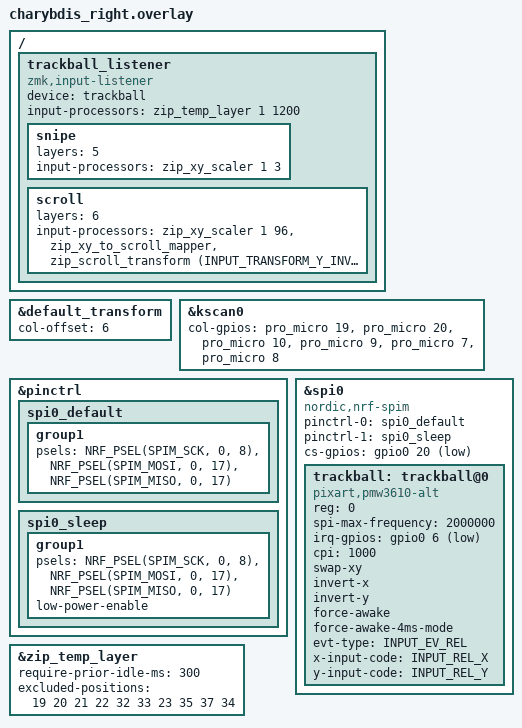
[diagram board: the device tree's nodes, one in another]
/*
 * Copyright (c) 2020 ZMK Contributors
 *
 * SPDX-License-Identifier: MIT
 */

#include <zephyr/dt-bindings/input/input-event-codes.h>
#include <dt-bindings/zmk/input_transform.h>
#include <input/processors.dtsi>

#include "charybdis.dtsi"

&default_transform {
	col-offset = <6>;
};

&kscan0 {
	col-gpios
		= <&pro_micro 19 GPIO_ACTIVE_HIGH>
		, <&pro_micro 20 GPIO_ACTIVE_HIGH>
		, <&pro_micro 10 GPIO_ACTIVE_HIGH>
		, <&pro_micro 9 GPIO_ACTIVE_HIGH>
		, <&pro_micro 7 GPIO_ACTIVE_HIGH>
		, <&pro_micro 8 GPIO_ACTIVE_HIGH>
		;
};

// trackball bus
&pinctrl {
    spi0_default: spi0_default {
        group1 {
            psels = <NRF_PSEL(SPIM_SCK, 0, 8)>,
                <NRF_PSEL(SPIM_MOSI, 0, 17)>,
                <NRF_PSEL(SPIM_MISO, 0, 17)>;
        };
    };

    spi0_sleep: spi0_sleep {
        group1 {
            psels = <NRF_PSEL(SPIM_SCK, 0, 8)>,
                <NRF_PSEL(SPIM_MOSI, 0, 17)>,
                <NRF_PSEL(SPIM_MISO, 0, 17)>;
            low-power-enable;
        };
    };
};

&spi0 {
    status = "okay";
    compatible = "nordic,nrf-spim";
    pinctrl-0 = <&spi0_default>;
    pinctrl-1 = <&spi0_sleep>;
    pinctrl-names = "default", "sleep";
    cs-gpios = <&gpio0 20 GPIO_ACTIVE_LOW>;

    trackball: trackball@0 {
        status = "okay";
        compatible = "pixart,pmw3610-alt";
        reg = <0>;
        spi-max-frequency = <2000000>;
        irq-gpios = <&gpio0 6 (GPIO_ACTIVE_LOW | GPIO_PULL_UP)>;

        /* pointer CPI — tune here for everyday move / snipe base */
        cpi = <1000>;

        /*
         * inorichi ORIENTATION_90 + INVERT_X:
         *   x = -raw_y; y = -raw_x  →  swap-xy + invert both axes
         */
        swap-xy;
        invert-x;
        invert-y;

        /*
         * Keep sensor in RUN while ZMK is ACTIVE so short idle does not
         * drop into REST2/REST3 (100–500ms sample) and feel laggy on wake.
         * After ZMK IDLE/SLEEP it falls back to normal downshift.
         *
         * 4ms RUN sampling (~250Hz): meaningful over USB to the central
         * (right) half; BLE to host cannot sustain that report rate.
         */
        force-awake;
        force-awake-4ms-mode;

        evt-type = <INPUT_EV_REL>;
        x-input-code = <INPUT_REL_X>;
        y-input-code = <INPUT_REL_Y>;
    };
};

/*
 * Sensor emits Zephyr input events; the listener turns them into HID.
 * Snipe / scroll / automouse used to live on the inorichi sensor node;
 * mainline does them with layer-scoped input processors instead.
 *
 * Override nodes run first (declaration order). A match skips the rest
 * unless process-next is set — so SNIPE/SCROLL do not also fire automouse.
 */

/*
 * Automouse guards:
 * - require-prior-idle-ms: ball bumps within 300ms of a keypress do not
 *   enable MOUSE, so typing j/k/l right after brushing the ball stays text.
 * - excluded-positions: pressing any other key closes MOUSE immediately.
 *   Listed keys keep it open: J K L ; (19-22), , . (32 33),
 *   SNIPE ' (23), SCROLL \ (35), Shift (37), Alt / (34).
 *   Add any new key placed on the MOUSE layer here too.
 */
&zip_temp_layer {
    require-prior-idle-ms = <300>;
    excluded-positions = <19 20 21 22 32 33 23 35 37 34>;
};

/ {
    trackball_listener {
        compatible = "zmk,input-listener";
        device = <&trackball>;

        /* layer 5 SNIPE: ~1/3 speed (old snipe CPI 800 / normal 2400) */
        snipe {
            layers = <5>;
            input-processors = <&zip_xy_scaler 1 3>;
        };

        /* layer 6 SCROLL: higher divisor = slower wheel; invert vertical */
        scroll {
            layers = <6>;
            input-processors =
                <&zip_xy_scaler 1 96>,
                <&zip_xy_to_scroll_mapper>,
                <&zip_scroll_transform (INPUT_TRANSFORM_Y_INVERT)>;
        };

        /* default: temp MOUSE layer for 1200ms after ball motion */
        input-processors = <&zip_temp_layer 1 1200>;
    };
};
